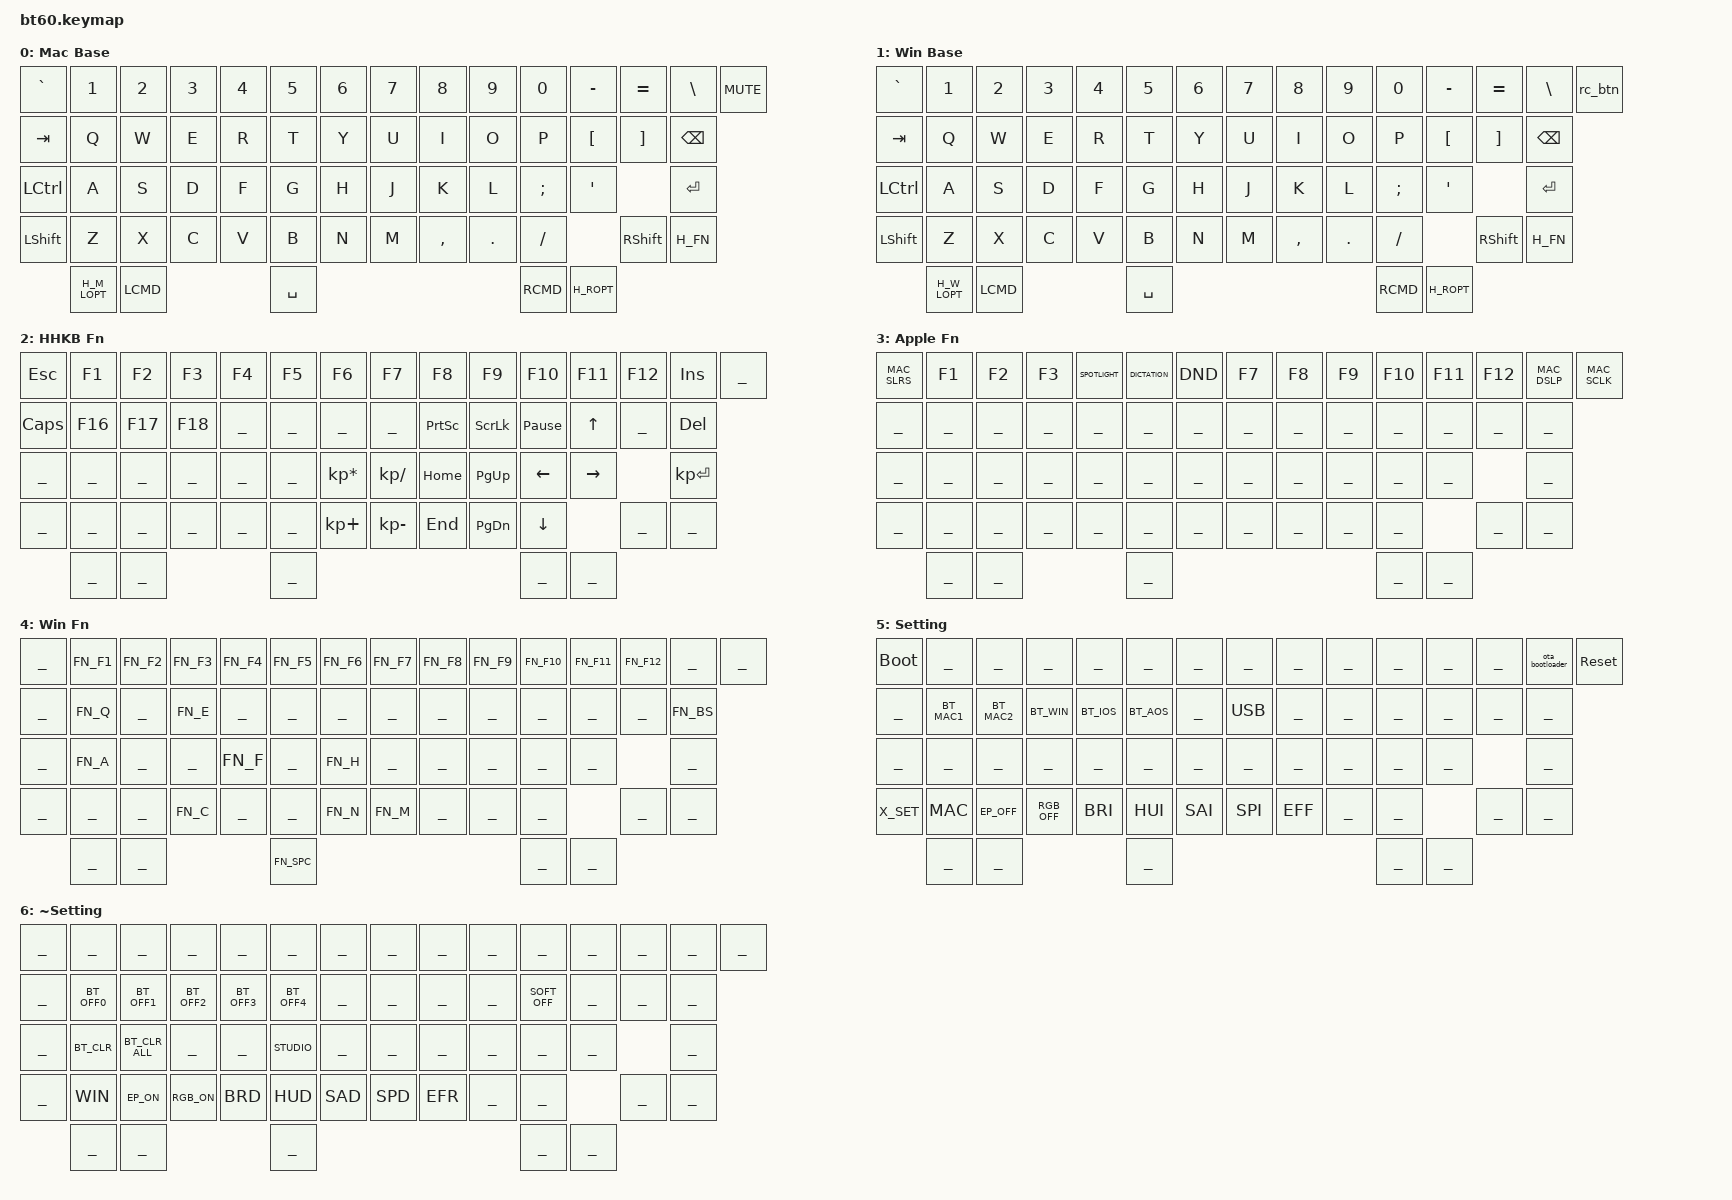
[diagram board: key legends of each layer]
#include "my-keymap-common.dtsi"

/ {
  keymap {
    compatible = "zmk,keymap";
    mac_base_layer {
      // -------------------------------------------------------------------------------------------
      // |  `  |  1  |  2  |  3  |  4  |  5  |  6  |  7  |  8  |  9  |  0  |  -  |  =  |  \  |EC11 |
      // -------------------------------------------------------------------------------------------
      // | TAB    |  Q  |  W  |  E  |  R  |  T  |  Y  |  U  |  I  |  O  |  P  |  [  |  ]  | Bkspc  |
      // -------------------------------------------------------------------------------------------
      // | CAPS     |  A  |  S  |  D  |  F  |  G  |  H  |  J  |  K  |  L  |  ;  |  '  |     ENTER  |
      // -------------------------------------------------------------------------------------------
      // |  SHIFT     |  Z  |  X  |  C  |  V  |  B  |  N  |  M  |  ,  |  .  |  /  |  SHIFT   | MO2 |
      // ------------------------------------------------------------------------------------------
      //          | Opt |  Cmd  |            SPACE                         |  Cmd   | Opt |
      //          -------------------------------------------------------------------------
      display-name = "Mac Base";
      bindings =
        <
         &kp GRAVE  &kp N1    &kp N2  &kp N3  &kp N4  &kp N5  &kp N6  &kp N7  &kp N8     &kp N9   &kp N0    &kp MINUS  &kp EQUAL  &kp BSLH  /* EC11 */ &kp C_MUTE
         &kp TAB    &kp Q     &kp W   &kp E   &kp R   &kp T   &kp Y   &kp U   &kp I      &kp O    &kp P     &kp LBKT   &kp RBKT             &kp BSPC
         &kp LCTRL  &kp A     &kp S   &kp D   &kp F   &kp G   &kp H   &kp J   &kp K      &kp L    &kp SEMI  &kp SQT                         &kp RET
         &kp LSHFT  &kp Z     &kp X   &kp C   &kp V   &kp B   &kp N   &kp M   &kp COMMA  &kp DOT  &kp FSLH             &kp RSHIFT           _H_FN
         /**/       _H_M_LOPT _LCMD                   &kp SPACE                                   _RCMD     _H_ROPT
        >;
      sensor-bindings = <&volume_encoder>;
    };
    win_base_layer {
      display-name = "Win Base";
      bindings =
        <
         &kp GRAVE  &kp N1    &kp N2  &kp N3  &kp N4  &kp N5  &kp N6  &kp N7  &kp N8     &kp N9   &kp N0    &kp MINUS  &kp EQUAL  &kp BSLH  /* EC11 */ &rc_btn
         &kp TAB    &kp Q     &kp W   &kp E   &kp R   &kp T   &kp Y   &kp U   &kp I      &kp O    &kp P     &kp LBKT   &kp RBKT             &kp BSPC
         &kp LCTRL  &kp A     &kp S   &kp D   &kp F   &kp G   &kp H   &kp J   &kp K      &kp L    &kp SEMI  &kp SQT                         &kp RET
         &kp LSHFT  &kp Z     &kp X   &kp C   &kp V   &kp B   &kp N   &kp M   &kp COMMA  &kp DOT  &kp FSLH             &kp RSHIFT           _H_FN
         /**/       _H_W_LOPT _LCMD                   &kp SPACE                                  _RCMD     _H_ROPT
        >;
      sensor-bindings = <&radial_controller>;
    };
    hhkb_fn_layer {
      display-name = "HHKB Fn";
      bindings =
        <
         &kp ESC    &kp F1     &kp F2   &kp F3   &kp F4  &kp F5  &kp F6           &kp F7         &kp F8     &kp F9     &kp F10          &kp F11   &kp F12  &kp INS  ______
         &kp CAPS   &kp F16    &kp F17  &kp F18  ______  ______  ______           ______         &kp PSCRN  &kp SLCK   &kp PAUSE_BREAK  &kp UP    ______            &kp DEL
         ______     ______     ______   ______   ______  ______  &kp KP_MULTIPLY  &kp KP_DIVIDE  &kp HOME   &kp PG_UP  &kp LEFT         &kp RIGHT                   &kp KP_ENTER
         ______     ______     ______   ______   ______  ______  &kp KP_PLUS      &kp KP_MINUS   &kp END    &kp PG_DN  &kp DOWN                   ______            ______
         /**/       ______     ______                                             ______                               ______           ______
        >;
      sensor-bindings = <&trans_encoder>;
    };
    apple_fn_layer {
      display-name = "Apple Fn";
      bindings =
        <
         _MAC_SLRS  &kp F1  &kp F2  &kp F3  _SPOTLIGHT _DICTATION  _DND    &kp F7  &kp F8  &kp F9  &kp F10  &kp F11  &kp F12  _MAC_DSLP  _MAC_SCLK
         ______     ______  ______  ______  ______     ______      ______  ______  ______  ______  ______   ______   ______              ______
         ______     ______  ______  ______  ______     ______      ______  ______  ______  ______  ______   ______                       ______
         ______     ______  ______  ______  ______     ______      ______  ______  ______  ______  ______            ______              ______
         /**/       ______  ______                                 ______                          ______   ______
        >;
      sensor-bindings = <&trans_encoder>;
    };
    win_fn_layer {
      display-name = "Win Fn";
      bindings =
        <
         ______  _FN_F1  _FN_F2  _FN_F3  _FN_F4  _FN_F5  _FN_F6  _FN_F7  _FN_F8  _FN_F9  _FN_F10 _FN_F11 _FN_F12  ______  ______
         ______  _FN_Q   ______  _FN_E   ______  ______  ______  ______  ______  ______  ______  ______  ______           _FN_BS
         ______  _FN_A   ______  ______  _FN_F   ______  _FN_H   ______  ______  ______  ______  ______                   ______
         ______  ______  ______  _FN_C   ______  ______  _FN_N   _FN_M   ______  ______  ______          ______           ______
         /**/    ______  ______                                  _FN_SPC                 ______  ______
        >;
      sensor-bindings = <&radial_controller_fine>;
    };
    setting_layer {
      // _SOFT_OFF
      //  To wake on any key-press, all other keys should be releeased before soft_off key being releasesd.
      //  if not wake on key press, connect/dis-connect USB.
      display-name = "Setting";
      bindings =
        <
         &bootloader  ______    ______    ______    ______    ______    ______   ______  ______  ______  ______  ______  ______  &ota_bootloader  &sys_reset
         ______       _BT_MAC1  _BT_MAC2  _BT_WIN   _BT_IOS   _BT_AOS   ______   _USB    ______  ______  ______  ______  ______                   ______
         ______       ______    ______    ______    ______    ______    ______   ______  ______  ______  ______  ______                           ______
         _X_SET       _MAC      _EP_OFF   _RGB_OFF  _BRI      _HUI      _SAI     _SPI    _EFF    ______  ______          ______                   ______
         /**/         ______    ______                                           ______                          ______  ______
        >;
      sensor-bindings = <&trans_encoder>;
    };
    inverse_setting_layer {
      display-name = "~Setting";
      bindings =
        <
         ______  ______    ______       ______    ______    ______    ______  ______  ______  ______  ______    ______  ______  ______  ______
         ______  _BT_OFF0  _BT_OFF1     _BT_OFF2  _BT_OFF3  _BT_OFF4  ______  ______  ______  ______  _SOFT_OFF ______  ______          ______
         ______  _BT_CLR   _BT_CLR_ALL  ______    ______    _STUDIO   ______  ______  ______  ______  ______    ______                  ______
         ______  _WIN      _EP_ON       _RGB_ON   _BRD      _HUD      _SAD    _SPD    _EFR    ______  ______            ______          ______
         /**/    ______    ______                           ______                          ______    ______
        >;
      sensor-bindings = <&trans_encoder>;
    };
  };
};

/*
 * Enable encoder_1
 * EC11E18244A5
 * https://tech.alpsalpine.com/e/products/detail/EC11E18244A5
 */
&encoder_1 {
  status = "okay";
};
